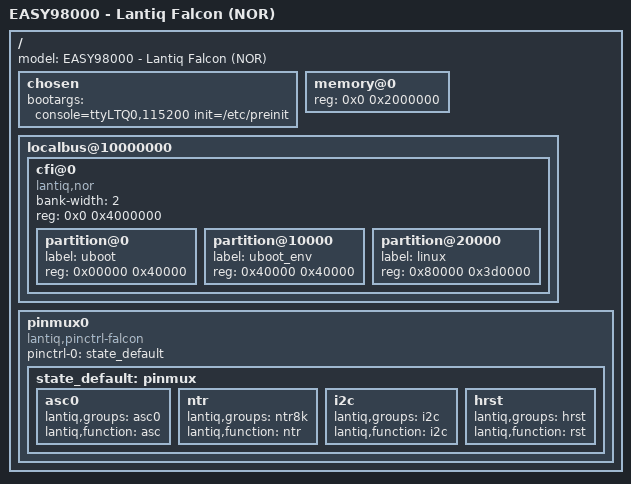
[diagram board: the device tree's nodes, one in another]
/dts-v1/;

/include/ "falcon.dtsi"

/ {
	model = "EASY98000 - Lantiq Falcon (NOR)";

	chosen {
		bootargs = "console=ttyLTQ0,115200 init=/etc/preinit";
	};

	memory@0 {
		reg = <0x0 0x2000000>;
	};
	
	localbus@10000000 {
		cfi@0 {
			compatible = "lantiq,nor";
			bank-width = <2>;
			reg = <0x0 0x4000000>;
			#address-cells = <1>;
			#size-cells = <1>;

			partition@0 {
				label = "uboot";
				reg = <0x00000 0x40000>;
			};

			partition@10000 {
				label = "uboot_env";
				reg = <0x40000 0x40000>;
			};

			partition@20000 {
				label = "linux";
				reg = <0x80000 0x3d0000>;
			};
		};
	};
	
	pinmux0 {
		compatible = "lantiq,pinctrl-falcon";
		pinctrl-names = "default";
		pinctrl-0 = <&state_default>;

		state_default: pinmux {
			asc0 {
				lantiq,groups = "asc0";
				lantiq,function = "asc";
			};
			ntr {
				lantiq,groups = "ntr8k";
				lantiq,function = "ntr";
			};
			i2c {
				lantiq,groups = "i2c";
				lantiq,function = "i2c";
			};
			hrst {
				lantiq,groups = "hrst";
				lantiq,function = "rst";
			};
		};
	};
};
